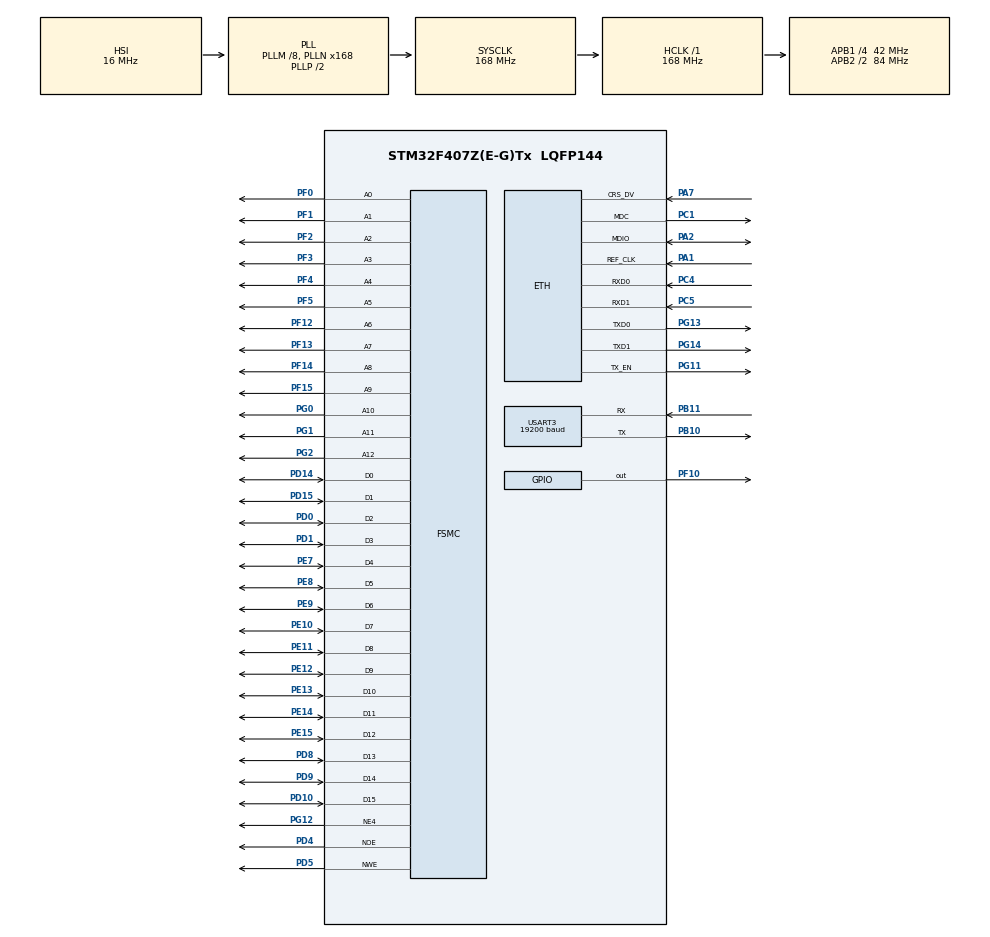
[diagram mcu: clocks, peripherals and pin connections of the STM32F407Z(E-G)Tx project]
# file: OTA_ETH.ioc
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ETH.MediaInterface=HAL_ETH_RMII_MODE
LWIP.BSP.number=1
LWIP.GATEWAY_ADDRESS=192.168.001.001
LWIP.IP_ADDRESS=192.168.001.002
LWIP.LWIP_DHCP=0
LWIP.LWIP_ICMP=1
LWIP.LWIP_IPV6=0
LWIP.LWIP_UDP=0
LWIP.NETMASK_ADDRESS=255.255.255.000
LWIP.TCP_MSS=1426
LWIP.Version=v2.1.2_Cube
LWIP0.BSP.STBoard=false
LWIP0.BSP.api=BSP_COMPONENT_DRIVER
LWIP0.BSP.component=LAN8742
LWIP0.BSP.instance=LAN8742
LWIP0.BSP.name=Driver_PHY
LWIP0.BSP.semaphore=S_LAN8742
LWIP0.BSP.solution=LAN8742
Mcu.Family=STM32F4
Mcu.Name=STM32F407Z(E-G)Tx
Mcu.Package=LQFP144
NVIC.PriorityGroup=NVIC_PRIORITYGROUP_4
NVIC.USART3_IRQn=true\:1\:0\:true\:false\:true\:true\:true\:true
PA1.Mode=RMII
PA1.Signal=ETH_REF_CLK
PA13.Mode=Serial_Wire
PA13.Signal=SYS_JTMS-SWDIO
PA14.Mode=Serial_Wire
PA14.Signal=SYS_JTCK-SWCLK
PA2.Mode=RMII
PA2.Signal=ETH_MDIO
PA7.Mode=RMII
PA7.Signal=ETH_CRS_DV
PB10.Mode=Asynchronous
PB10.Signal=USART3_TX
PB11.Mode=Asynchronous
PB11.Signal=USART3_RX
PC1.Mode=RMII
PC1.Signal=ETH_MDC
PC4.Mode=RMII
PC4.Signal=ETH_RXD0
PC5.Mode=RMII
PC5.Signal=ETH_RXD1
PD0.Signal=FSMC_D2_DA2
PD1.Signal=FSMC_D3_DA3
PD10.Signal=FSMC_D15_DA15
PD14.Signal=FSMC_D0_DA0
PD15.Signal=FSMC_D1_DA1
PD4.Signal=FSMC_NOE
PD5.Signal=FSMC_NWE
PD8.Signal=FSMC_D13_DA13
PD9.Signal=FSMC_D14_DA14
PE10.Signal=FSMC_D7_DA7
PE11.Signal=FSMC_D8_DA8
PE12.Signal=FSMC_D9_DA9
PE13.Signal=FSMC_D10_DA10
PE14.Signal=FSMC_D11_DA11
PE15.Signal=FSMC_D12_DA12
PE7.Signal=FSMC_D4_DA4
PE8.Signal=FSMC_D5_DA5
PE9.Signal=FSMC_D6_DA6
PF0.Signal=FSMC_A0
PF1.Signal=FSMC_A1
PF10.Signal=GPIO_Output
PF12.Signal=FSMC_A6
PF13.Signal=FSMC_A7
PF14.Signal=FSMC_A8
PF15.Signal=FSMC_A9
PF2.Signal=FSMC_A2
PF3.Signal=FSMC_A3
PF4.Signal=FSMC_A4
PF5.Signal=FSMC_A5
PG0.Signal=FSMC_A10
PG1.Signal=FSMC_A11
PG11.Mode=RMII
PG11.Signal=ETH_TX_EN
PG12.Mode=NorPsramChipSelect4_4
PG12.Signal=FSMC_NE4
PG13.Mode=RMII
PG13.Signal=ETH_TXD0
PG14.Mode=RMII
PG14.Signal=ETH_TXD1
PG2.Signal=FSMC_A12
ProjectManager.HeapSize=0x200
ProjectManager.StackSize=0x400
ProjectManager.TargetToolchain=MDK-ARM V5.32
RCC.48MHZClocksFreq_Value=84000000
RCC.AHBFreq_Value=168000000
RCC.APB1CLKDivider=RCC_HCLK_DIV4
RCC.APB1Freq_Value=42000000
RCC.APB1TimFreq_Value=84000000
RCC.APB2CLKDivider=RCC_HCLK_DIV2
RCC.APB2Freq_Value=84000000
RCC.APB2TimFreq_Value=168000000
RCC.CortexFreq_Value=168000000
RCC.HCLKFreq_Value=168000000
RCC.HSE_VALUE=25000000
RCC.HSI_VALUE=16000000
RCC.LSE_VALUE=32768
RCC.PLLM=8
RCC.PLLN=168
RCC.SYSCLKFreq_VALUE=168000000
RCC.SYSCLKSource=RCC_SYSCLKSOURCE_PLLCLK
RCC.VCOOutputFreq_Value=336000000
SH.FSMC_A0.0=FSMC_A0,13b-a4
SH.FSMC_A1.0=FSMC_A1,13b-a4
SH.FSMC_A10.0=FSMC_A10,13b-a4
SH.FSMC_A11.0=FSMC_A11,13b-a4
SH.FSMC_A12.0=FSMC_A12,13b-a4
SH.FSMC_A2.0=FSMC_A2,13b-a4
SH.FSMC_A3.0=FSMC_A3,13b-a4
SH.FSMC_A4.0=FSMC_A4,13b-a4
SH.FSMC_A5.0=FSMC_A5,13b-a4
SH.FSMC_A6.0=FSMC_A6,13b-a4
SH.FSMC_A7.0=FSMC_A7,13b-a4
SH.FSMC_A8.0=FSMC_A8,13b-a4
SH.FSMC_A9.0=FSMC_A9,13b-a4
SH.FSMC_D0_DA0.0=FSMC_D0,16b-d4
SH.FSMC_D10_DA10.0=FSMC_D10,16b-d4
SH.FSMC_D11_DA11.0=FSMC_D11,16b-d4
SH.FSMC_D12_DA12.0=FSMC_D12,16b-d4
SH.FSMC_D13_DA13.0=FSMC_D13,16b-d4
SH.FSMC_D14_DA14.0=FSMC_D14,16b-d4
SH.FSMC_D15_DA15.0=FSMC_D15,16b-d4
SH.FSMC_D1_DA1.0=FSMC_D1,16b-d4
SH.FSMC_D2_DA2.0=FSMC_D2,16b-d4
SH.FSMC_D3_DA3.0=FSMC_D3,16b-d4
SH.FSMC_D4_DA4.0=FSMC_D4,16b-d4
SH.FSMC_D5_DA5.0=FSMC_D5,16b-d4
SH.FSMC_D6_DA6.0=FSMC_D6,16b-d4
SH.FSMC_D7_DA7.0=FSMC_D7,16b-d4
SH.FSMC_D8_DA8.0=FSMC_D8,16b-d4
SH.FSMC_D9_DA9.0=FSMC_D9,16b-d4
SH.FSMC_NOE.0=FSMC_NOE,Sram4
SH.FSMC_NWE.0=FSMC_NWE,Sram4
USART3.BaudRate=19200
USART3.VirtualMode=VM_ASYNC
VP_LWIP_VS_Enabled.Mode=Enabled
board=custom

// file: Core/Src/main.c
/* USER CODE BEGIN Header */
/**
  ******************************************************************************
  * @file           : main.c
  * @brief          : Main program body
  ******************************************************************************
  * @attention
  *
  * Copyright (c) 2026 STMicroelectronics.
  * All rights reserved.
  *
  * This software is licensed under terms that can be found in the LICENSE file
  * in the root directory of this software component.
  * If no LICENSE file comes with this software, it is provided AS-IS.
  *
  ******************************************************************************
  */
/* USER CODE END Header */
#include "main.h"
#include "lwip.h"
#include "usart.h"
#include "gpio.h"
#include "fsmc.h"

/* USER CODE BEGIN Includes */
#include "lcd.h"
#include "flash_if.h"
#include "Bootloader.h"
/* USER CODE END Includes */

/* USER CODE BEGIN PV */

static uint8_t flash_selftest;
/* USER CODE END PV */

void SystemClock_Config(void);

int main(void)
{

  /* MCU Configuration--------------------------------------------------------*/

  /* Reset of all peripherals, Initializes the Flash interface and the Systick. */
  HAL_Init();

  /* Configure the system clock */
  SystemClock_Config();

  /* Initialize all configured peripherals */
  MX_GPIO_Init();
  MX_LWIP_Init();
  MX_FSMC_Init();
  MX_USART3_UART_Init();
  /* USER CODE BEGIN 2 */
  LCD_Init();

  Bootloader_Init();   /* 帧状态机复位 + 注入发送出口 + 起 TCP 监听 + 开串口接收中断 */
  Bootloader_Run();    /* 5s 等待窗口 → 启动决策 / 常驻下载；跳转 app 则永不返回 */
  /* USER CODE END 2 */

  /* Infinite loop */
  /* USER CODE BEGIN WHILE */
  while (1)
  {
    /* 不可达：Bootloader_Run() 要么跳转到运行区 app，要么进入常驻下载死循环。
     * 保留空循环仅为满足 CubeMX 模板结构。 */
    /* USER CODE END WHILE */

  }
}

void SystemClock_Config(void)
{
  RCC_OscInitTypeDef RCC_OscInitStruct = {0};
  RCC_ClkInitTypeDef RCC_ClkInitStruct = {0};

  /** Configure the main internal regulator output voltage
  */
  __HAL_RCC_PWR_CLK_ENABLE();
  __HAL_PWR_VOLTAGESCALING_CONFIG(PWR_REGULATOR_VOLTAGE_SCALE1);

  /** Initializes the RCC Oscillators according to the specified parameters
  * in the RCC_OscInitTypeDef structure.
  */
  RCC_OscInitStruct.OscillatorType = RCC_OSCILLATORTYPE_HSI;
  RCC_OscInitStruct.HSIState = RCC_HSI_ON;
  RCC_OscInitStruct.HSICalibrationValue = RCC_HSICALIBRATION_DEFAULT;
  RCC_OscInitStruct.PLL.PLLState = RCC_PLL_ON;
  RCC_OscInitStruct.PLL.PLLSource = RCC_PLLSOURCE_HSI;
  RCC_OscInitStruct.PLL.PLLM = 8;
  RCC_OscInitStruct.PLL.PLLN = 168;
  RCC_OscInitStruct.PLL.PLLP = RCC_PLLP_DIV2;
  RCC_OscInitStruct.PLL.PLLQ = 4;
  if (HAL_RCC_OscConfig(&RCC_OscInitStruct) != HAL_OK)
  {
    Error_Handler();
  }

  /** Initializes the CPU, AHB and APB buses clocks
  */
  RCC_ClkInitStruct.ClockType = RCC_CLOCKTYPE_HCLK|RCC_CLOCKTYPE_SYSCLK
                              |RCC_CLOCKTYPE_PCLK1|RCC_CLOCKTYPE_PCLK2;
  RCC_ClkInitStruct.SYSCLKSource = RCC_SYSCLKSOURCE_PLLCLK;
  RCC_ClkInitStruct.AHBCLKDivider = RCC_SYSCLK_DIV1;
  RCC_ClkInitStruct.APB1CLKDivider = RCC_HCLK_DIV4;
  RCC_ClkInitStruct.APB2CLKDivider = RCC_HCLK_DIV2;

  if (HAL_RCC_ClockConfig(&RCC_ClkInitStruct, FLASH_LATENCY_5) != HAL_OK)
  {
    Error_Handler();
  }
}

void Error_Handler(void)
{
  __disable_irq();
  while (1)
  {
  }
}
